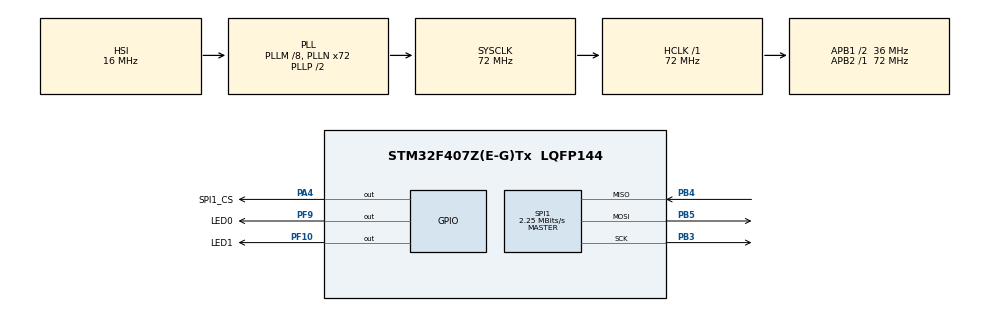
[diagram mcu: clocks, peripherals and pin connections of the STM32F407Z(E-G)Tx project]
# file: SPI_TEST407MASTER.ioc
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Mcu.Family=STM32F4
Mcu.Name=STM32F407Z(E-G)Tx
Mcu.Package=LQFP144
NVIC.PriorityGroup=NVIC_PRIORITYGROUP_4
NVIC.SPI1_IRQn=true\:0\:0\:false\:false\:true\:true\:true\:true
PA13.Mode=Serial_Wire
PA13.Signal=SYS_JTMS-SWDIO
PA14.Mode=Serial_Wire
PA14.Signal=SYS_JTCK-SWCLK
PA4.GPIO_Label=SPI1_CS
PA4.GPIO_Speed=GPIO_SPEED_FREQ_HIGH
PA4.PinState=GPIO_PIN_SET
PA4.Signal=GPIO_Output
PB3.Mode=Full_Duplex_Master
PB3.Signal=SPI1_SCK
PB4.Mode=Full_Duplex_Master
PB4.Signal=SPI1_MISO
PB5.Mode=Full_Duplex_Master
PB5.Signal=SPI1_MOSI
PF10.GPIO_Label=LED1
PF10.GPIO_Speed=GPIO_SPEED_FREQ_HIGH
PF10.PinState=GPIO_PIN_SET
PF10.Signal=GPIO_Output
PF9.GPIO_Label=LED0
PF9.GPIO_Speed=GPIO_SPEED_FREQ_HIGH
PF9.PinState=GPIO_PIN_SET
PF9.Signal=GPIO_Output
PH0-OSC_IN.Mode=HSE-External-Oscillator
PH0-OSC_IN.Signal=RCC_OSC_IN
PH1-OSC_OUT.Mode=HSE-External-Oscillator
PH1-OSC_OUT.Signal=RCC_OSC_OUT
ProjectManager.HeapSize=0x200
ProjectManager.StackSize=0x400
ProjectManager.TargetToolchain=MDK-ARM V5.32
RCC.48MHZClocksFreq_Value=36000000
RCC.AHBFreq_Value=72000000
RCC.APB1CLKDivider=RCC_HCLK_DIV2
RCC.APB1Freq_Value=36000000
RCC.APB1TimFreq_Value=72000000
RCC.APB2Freq_Value=72000000
RCC.APB2TimFreq_Value=72000000
RCC.CortexFreq_Value=72000000
RCC.HCLKFreq_Value=72000000
RCC.HSE_VALUE=25000000
RCC.HSI_VALUE=16000000
RCC.LSE_VALUE=32768
RCC.PLLM=8
RCC.PLLN=72
RCC.SYSCLKFreq_VALUE=72000000
RCC.SYSCLKSource=RCC_SYSCLKSOURCE_PLLCLK
RCC.VCOOutputFreq_Value=144000000
SPI1.BaudRatePrescaler=SPI_BAUDRATEPRESCALER_32
SPI1.CLKPhase=SPI_PHASE_2EDGE
SPI1.CLKPolarity=SPI_POLARITY_HIGH
SPI1.CalculateBaudRate=2.25 MBits/s
SPI1.DataSize=SPI_DATASIZE_16BIT
SPI1.Direction=SPI_DIRECTION_2LINES
SPI1.Mode=SPI_MODE_MASTER
SPI1.VirtualType=VM_MASTER
board=custom

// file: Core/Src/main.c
/* USER CODE BEGIN Header */
/**
  ******************************************************************************
  * @file           : main.c
  * @brief          : Main program body
  ******************************************************************************
  * @attention
  *
  * Copyright (c) 2025 STMicroelectronics.
  * All rights reserved.
  *
  * This software is licensed under terms that can be found in the LICENSE file
  * in the root directory of this software component.
  * If no LICENSE file comes with this software, it is provided AS-IS.
  *
  ******************************************************************************
  */
/* USER CODE END Header */
#include "main.h"
#include "spi.h"
#include "gpio.h"

/* USER CODE BEGIN PV */
uint16_t spi_rxData = 0;
/* USER CODE END PV */

void SystemClock_Config(void);

int main(void)
{

  /* USER CODE BEGIN 1 */
uint16_t spi_ctrl = 0x00, disposal_cnt = 60000, read_cnt = 40000;
  /* USER CODE END 1 */

  /* MCU Configuration--------------------------------------------------------*/

  /* Reset of all peripherals, Initializes the Flash interface and the Systick. */
  HAL_Init();

  /* Configure the system clock */
  SystemClock_Config();

  /* Initialize all configured peripherals */
  MX_GPIO_Init();
  MX_SPI1_Init();

  /* Infinite loop */
  while (1)
  {
        // SPI通信传输DATA_DISPOSAL_COUNT还是DATA_READ_COUNT
        spi_ctrl = 0;
        spi_ctrl &= 0x7FFF;  // bit15, 0-write data, 1-read data;
        spi_ctrl |= 1 << 14; // bit14, disposal_cnt flag;
				spi1_write_bit16(spi_ctrl & 0xFFFF);
        spi1_write_bit16(disposal_cnt & 0xFFFF);

                spi_ctrl = 0;
                spi_ctrl &= 0x7FFF;           // bit15, 0-write data, 1-read data;
                spi_ctrl |= 1 << 13;           // bit13, DATA READCOUNT flag;

                spi1_write_bit16(spi_ctrl & 0xFFFF);
                spi1_write_bit16(read_cnt & 0xFFFF);

				spi_ctrl = 0x8000;
				spi1_write_bit16(spi_ctrl & 0xFFFF);
        spi_rxData =spi1_read_bit16();
    /* USER CODE BEGIN 3 */
		HAL_Delay(5000);
		HAL_GPIO_TogglePin(LED0_GPIO_Port,LED0_Pin);
  }
  /* USER CODE END 3 */
}

void SystemClock_Config(void)
{
  RCC_OscInitTypeDef RCC_OscInitStruct = {0};
  RCC_ClkInitTypeDef RCC_ClkInitStruct = {0};

  /** Configure the main internal regulator output voltage
  */
  __HAL_RCC_PWR_CLK_ENABLE();
  __HAL_PWR_VOLTAGESCALING_CONFIG(PWR_REGULATOR_VOLTAGE_SCALE1);

  /** Initializes the RCC Oscillators according to the specified parameters
  * in the RCC_OscInitTypeDef structure.
  */
  RCC_OscInitStruct.OscillatorType = RCC_OSCILLATORTYPE_HSI;
  RCC_OscInitStruct.HSIState = RCC_HSI_ON;
  RCC_OscInitStruct.HSICalibrationValue = RCC_HSICALIBRATION_DEFAULT;
  RCC_OscInitStruct.PLL.PLLState = RCC_PLL_ON;
  RCC_OscInitStruct.PLL.PLLSource = RCC_PLLSOURCE_HSI;
  RCC_OscInitStruct.PLL.PLLM = 8;
  RCC_OscInitStruct.PLL.PLLN = 72;
  RCC_OscInitStruct.PLL.PLLP = RCC_PLLP_DIV2;
  RCC_OscInitStruct.PLL.PLLQ = 4;
  if (HAL_RCC_OscConfig(&RCC_OscInitStruct) != HAL_OK)
  {
    Error_Handler();
  }

  /** Initializes the CPU, AHB and APB buses clocks
  */
  RCC_ClkInitStruct.ClockType = RCC_CLOCKTYPE_HCLK|RCC_CLOCKTYPE_SYSCLK
                              |RCC_CLOCKTYPE_PCLK1|RCC_CLOCKTYPE_PCLK2;
  RCC_ClkInitStruct.SYSCLKSource = RCC_SYSCLKSOURCE_PLLCLK;
  RCC_ClkInitStruct.AHBCLKDivider = RCC_SYSCLK_DIV1;
  RCC_ClkInitStruct.APB1CLKDivider = RCC_HCLK_DIV2;
  RCC_ClkInitStruct.APB2CLKDivider = RCC_HCLK_DIV1;

  if (HAL_RCC_ClockConfig(&RCC_ClkInitStruct, FLASH_LATENCY_2) != HAL_OK)
  {
    Error_Handler();
  }
}

void Error_Handler(void)
{
  __disable_irq();
  while (1)
  {
  }
}
